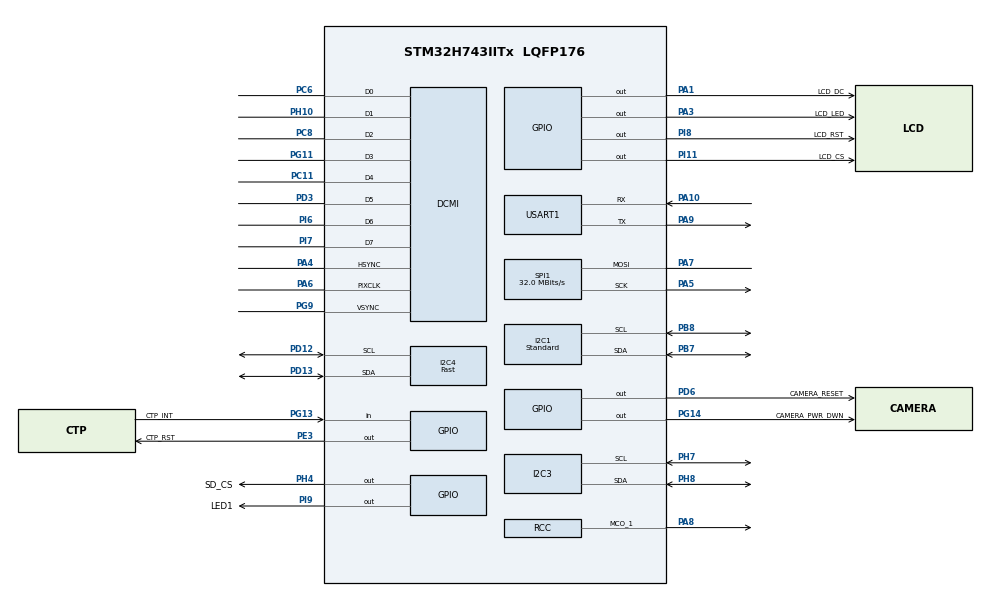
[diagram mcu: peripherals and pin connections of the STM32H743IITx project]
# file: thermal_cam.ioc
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CORTEX_M7.CPU_DCache=Disabled
CORTEX_M7.CPU_ICache=Disabled
CORTEX_M7.Enable_Spec=__NULL
CORTEX_M7.MPU_Control=__NULL
CORTEX_M7.default_mode_Activation=1
DCMI.HSPolarity=DCMI_HSPOLARITY_LOW
DCMI.PCKPolarity=DCMI_PCKPOLARITY_RISING
DCMI.VSPolarity=DCMI_VSPOLARITY_HIGH
Dma.DCMI.1.Direction=DMA_PERIPH_TO_MEMORY
Dma.DCMI.1.EventEnable=DISABLE
Dma.DCMI.1.FIFOMode=DMA_FIFOMODE_DISABLE
Dma.DCMI.1.Instance=DMA1_Stream2
Dma.DCMI.1.MemDataAlignment=DMA_MDATAALIGN_WORD
Dma.DCMI.1.MemInc=DMA_MINC_ENABLE
Dma.DCMI.1.Mode=DMA_NORMAL
Dma.DCMI.1.PeriphDataAlignment=DMA_PDATAALIGN_WORD
Dma.DCMI.1.PeriphInc=DMA_PINC_DISABLE
Dma.DCMI.1.Polarity=HAL_DMAMUX_REQ_GEN_RISING
Dma.DCMI.1.Priority=DMA_PRIORITY_LOW
Dma.DCMI.1.RequestNumber=1
Dma.DCMI.1.SignalID=NONE
Dma.DCMI.1.SyncEnable=DISABLE
Dma.DCMI.1.SyncPolarity=HAL_DMAMUX_SYNC_NO_EVENT
Dma.DCMI.1.SyncRequestNumber=1
Dma.DCMI.1.SyncSignalID=NONE
Dma.Request0=USART1_RX
Dma.Request1=DCMI
Dma.Request2=SPI1_TX
Dma.SPI1_TX.2.Direction=DMA_MEMORY_TO_PERIPH
Dma.SPI1_TX.2.EventEnable=DISABLE
Dma.SPI1_TX.2.FIFOMode=DMA_FIFOMODE_DISABLE
Dma.SPI1_TX.2.Instance=DMA1_Stream1
Dma.SPI1_TX.2.MemDataAlignment=DMA_MDATAALIGN_HALFWORD
Dma.SPI1_TX.2.MemInc=DMA_MINC_ENABLE
Dma.SPI1_TX.2.Mode=DMA_NORMAL
Dma.SPI1_TX.2.PeriphDataAlignment=DMA_PDATAALIGN_HALFWORD
Dma.SPI1_TX.2.PeriphInc=DMA_PINC_DISABLE
Dma.SPI1_TX.2.Polarity=HAL_DMAMUX_REQ_GEN_RISING
Dma.SPI1_TX.2.Priority=DMA_PRIORITY_LOW
Dma.SPI1_TX.2.RequestNumber=1
Dma.SPI1_TX.2.SignalID=NONE
Dma.SPI1_TX.2.SyncEnable=DISABLE
Dma.SPI1_TX.2.SyncPolarity=HAL_DMAMUX_SYNC_NO_EVENT
Dma.SPI1_TX.2.SyncRequestNumber=1
Dma.SPI1_TX.2.SyncSignalID=NONE
Dma.USART1_RX.0.Direction=DMA_PERIPH_TO_MEMORY
Dma.USART1_RX.0.EventEnable=DISABLE
Dma.USART1_RX.0.FIFOMode=DMA_FIFOMODE_DISABLE
Dma.USART1_RX.0.Instance=DMA1_Stream0
Dma.USART1_RX.0.MemDataAlignment=DMA_MDATAALIGN_BYTE
Dma.USART1_RX.0.MemInc=DMA_MINC_ENABLE
Dma.USART1_RX.0.Mode=DMA_CIRCULAR
Dma.USART1_RX.0.PeriphDataAlignment=DMA_PDATAALIGN_BYTE
Dma.USART1_RX.0.PeriphInc=DMA_PINC_DISABLE
Dma.USART1_RX.0.Polarity=HAL_DMAMUX_REQ_GEN_RISING
Dma.USART1_RX.0.Priority=DMA_PRIORITY_LOW
Dma.USART1_RX.0.RequestNumber=1
Dma.USART1_RX.0.SignalID=NONE
Dma.USART1_RX.0.SyncEnable=DISABLE
Dma.USART1_RX.0.SyncPolarity=HAL_DMAMUX_SYNC_NO_EVENT
Dma.USART1_RX.0.SyncRequestNumber=1
Dma.USART1_RX.0.SyncSignalID=NONE
FREERTOS.BinarySemaphores01=thermalSem,Dynamic,NULL,Depleted;RGBSem,Dynamic,NULL,Depleted
FREERTOS.Tasks01=defaultTask,24,128,StartDefaultTask,Default,NULL,Dynamic,NULL,NULL;cli_thread,24,256,cliThread,As external,NULL,Dynamic,NULL,NULL;lvgl_thread,32,6144,lvglThread,As external,NULL,Dynamic,NULL,NULL;thermal_thread,24,1024,thermalThread,As external,NULL,Dynamic,NULL,NULL;RGB_thread,24,2048,RGBThread,As external,NULL,Dynamic,NULL,NULL;BPM_Thread,24,2048,BPMThread,As external,NULL,Dynamic,NULL,NULL;BPM_Thread2,24,1024,BPMThread2,As external,NULL,Dynamic,NULL,NULL
FREERTOS.configCHECK_FOR_STACK_OVERFLOW=2
FREERTOS.configENABLE_FPU=1
FREERTOS.configTOTAL_HEAP_SIZE=64000
FREERTOS.configUSE_MALLOC_FAILED_HOOK=1
FREERTOS.configUSE_NEWLIB_REENTRANT=1
I2C1.I2C_Speed_Mode=I2C_Standard
I2C1.Timing=0x307075B1
I2C3.Timing=0x307075B1
I2C4.I2C_Speed_Mode=I2C_Fast
I2C4.Timing=0x00B03FDB
Mcu.Family=STM32H7
Mcu.Name=STM32H743IITx
Mcu.Package=LQFP176
NVIC.DCMI_IRQn=true\:5\:0\:false\:false\:true\:true\:true\:true\:true
NVIC.DMA1_Stream0_IRQn=true\:5\:0\:false\:false\:true\:true\:false\:true\:true
NVIC.DMA1_Stream1_IRQn=true\:5\:0\:false\:false\:true\:true\:false\:true\:true
NVIC.DMA1_Stream2_IRQn=true\:5\:0\:false\:false\:true\:true\:false\:true\:true
NVIC.PriorityGroup=NVIC_PRIORITYGROUP_4
NVIC.SPI1_IRQn=true\:5\:0\:false\:false\:true\:true\:false\:true\:true
NVIC.TIM16_IRQn=true\:5\:0\:false\:false\:true\:true\:true\:true\:true
NVIC.TIM7_IRQn=true\:15\:0\:false\:false\:true\:false\:false\:true\:true
NVIC.TimeBase=TIM7_IRQn
NVIC.TimeBaseIP=TIM7
PA1.GPIO_Label=LCD_DC
PA1.GPIO_Speed=GPIO_SPEED_FREQ_LOW
PA1.PinState=GPIO_PIN_RESET
PA1.Signal=GPIO_Output
PA10.Mode=Asynchronous
PA10.PinAttribute=Free
PA10.Signal=USART1_RX
PA13\ (JTMS/SWDIO).Mode=Serial_Wire
PA13\ (JTMS/SWDIO).PinAttribute=Free
PA13\ (JTMS/SWDIO).Signal=DEBUG_JTMS-SWDIO
PA14\ (JTCK/SWCLK).Mode=Serial_Wire
PA14\ (JTCK/SWCLK).PinAttribute=Free
PA14\ (JTCK/SWCLK).Signal=DEBUG_JTCK-SWCLK
PA3.GPIO_Label=LCD_LED
PA3.Signal=GPIO_Output
PA4.GPIO_PuPd=GPIO_NOPULL
PA4.GPIO_Speed=GPIO_SPEED_FREQ_LOW
PA4.Mode=Slave_8_bits_External_Synchro
PA4.Signal=DCMI_HSYNC
PA5.Mode=Simplex_Bidirectional_Master
PA5.Signal=SPI1_SCK
PA6.GPIO_PuPd=GPIO_NOPULL
PA6.GPIO_Speed=GPIO_SPEED_FREQ_LOW
PA6.Mode=Slave_8_bits_External_Synchro
PA6.Signal=DCMI_PIXCLK
PA7.GPIO_Speed=GPIO_SPEED_FREQ_LOW
PA7.Mode=Simplex_Bidirectional_Master
PA7.Signal=SPI1_MOSI
PA8.Mode=Clock-out-1
PA8.Signal=RCC_MCO_1
PA9.Mode=Asynchronous
PA9.PinAttribute=Free
PA9.Signal=USART1_TX
PB7.GPIO_Pu=GPIO_NOPULL
PB7.GPIO_Speed=GPIO_SPEED_FREQ_LOW
PB7.Mode=I2C
PB7.Signal=I2C1_SDA
PB8.GPIO_Pu=GPIO_NOPULL
PB8.GPIO_Speed=GPIO_SPEED_FREQ_LOW
PB8.Mode=I2C
PB8.Signal=I2C1_SCL
PC11.GPIO_PuPd=GPIO_NOPULL
PC11.GPIO_Speed=GPIO_SPEED_FREQ_LOW
PC11.Mode=Slave_8_bits_External_Synchro
PC11.Signal=DCMI_D4
PC14-OSC32_IN\ (OSC32_IN).Mode=LSE-External-Oscillator
PC14-OSC32_IN\ (OSC32_IN).Signal=RCC_OSC32_IN
PC15-OSC32_OUT\ (OSC32_OUT).Mode=LSE-External-Oscillator
PC15-OSC32_OUT\ (OSC32_OUT).Signal=RCC_OSC32_OUT
PC6.GPIO_PuPd=GPIO_NOPULL
PC6.GPIO_Speed=GPIO_SPEED_FREQ_LOW
PC6.Mode=Slave_8_bits_External_Synchro
PC6.PinAttribute=Free
PC6.Signal=DCMI_D0
PC8.GPIO_PuPd=GPIO_NOPULL
PC8.GPIO_Speed=GPIO_SPEED_FREQ_LOW
PC8.Mode=Slave_8_bits_External_Synchro
PC8.PinAttribute=Free
PC8.Signal=DCMI_D2
PD12.Mode=I2C
PD12.PinAttribute=Free
PD12.Signal=I2C4_SCL
PD13.Mode=I2C
PD13.PinAttribute=Free
PD13.Signal=I2C4_SDA
PD3.GPIO_PuPd=GPIO_NOPULL
PD3.GPIO_Speed=GPIO_SPEED_FREQ_LOW
PD3.Mode=Slave_8_bits_External_Synchro
PD3.PinAttribute=Free
PD3.Signal=DCMI_D5
PD6.GPIO_Label=CAMERA_RESET
PD6.Signal=GPIO_Output
PE3.GPIO_Label=CTP_RST
PE3.PinState=GPIO_PIN_SET
PE3.Signal=GPIO_Output
PG11.GPIO_PuPd=GPIO_NOPULL
PG11.GPIO_Speed=GPIO_SPEED_FREQ_LOW
PG11.Mode=Slave_8_bits_External_Synchro
PG11.Signal=DCMI_D3
PG13.GPIO_Label=CTP_INT
PG13.GPIO_PuPd=GPIO_PULLUP
PG13.Signal=GPIO_Input
PG14.GPIO_Label=CAMERA_PWR_DWN
PG14.Signal=GPIO_Output
PG9.GPIO_PuPd=GPIO_NOPULL
PG9.GPIO_Speed=GPIO_SPEED_FREQ_LOW
PG9.Mode=Slave_8_bits_External_Synchro
PG9.PinAttribute=Free
PG9.Signal=DCMI_VSYNC
PH0-OSC_IN\ (PH0).Mode=HSE-External-Oscillator
PH0-OSC_IN\ (PH0).Signal=RCC_OSC_IN
PH1-OSC_OUT\ (PH1).Mode=HSE-External-Oscillator
PH1-OSC_OUT\ (PH1).Signal=RCC_OSC_OUT
PH10.GPIO_PuPd=GPIO_NOPULL
PH10.GPIO_Speed=GPIO_SPEED_FREQ_LOW
PH10.Mode=Slave_8_bits_External_Synchro
PH10.PinAttribute=Free
PH10.Signal=DCMI_D1
PH2.Signal=FMC_SDCKE0
PH3.Signal=FMC_SDNE0
PH4.GPIO_Label=SD_CS
PH4.PinState=GPIO_PIN_SET
PH4.Signal=GPIO_Output
PH5.Signal=FMC_SDNWE
PH7.GPIO_Pu=GPIO_PULLUP
PH7.Mode=I2C
PH7.Signal=I2C3_SCL
PH8.GPIO_Pu=GPIO_PULLUP
PH8.Mode=I2C
PH8.Signal=I2C3_SDA
PI11.GPIO_Label=LCD_CS
PI11.GPIO_Speed=GPIO_SPEED_FREQ_LOW
PI11.Signal=GPIO_Output
PI6.GPIO_PuPd=GPIO_NOPULL
PI6.GPIO_Speed=GPIO_SPEED_FREQ_LOW
PI6.Mode=Slave_8_bits_External_Synchro
PI6.Signal=DCMI_D6
PI7.GPIO_PuPd=GPIO_NOPULL
PI7.GPIO_Speed=GPIO_SPEED_FREQ_LOW
PI7.Mode=Slave_8_bits_External_Synchro
PI7.Signal=DCMI_D7
PI8.GPIO_Label=LCD_RST
PI8.Signal=GPIO_Output
PI9.GPIO_Label=LED1
PI9.Signal=GPIO_Output
ProjectManager.HeapSize=0x200
ProjectManager.StackSize=0x400
ProjectManager.TargetToolchain=STM32CubeIDE
RCC.ADCFreq_Value=75000000
RCC.APB1Freq_Value=120000000
RCC.APB2Freq_Value=120000000
RCC.APB3Freq_Value=120000000
RCC.APB4Freq_Value=120000000
RCC.CortexFreq_Value=480000000
RCC.D1PPRE=RCC_APB3_DIV2
RCC.D2PPRE1=RCC_APB1_DIV2
RCC.D2PPRE2=RCC_APB2_DIV2
RCC.D3PPRE=RCC_APB4_DIV2
RCC.DIVM1=5
RCC.DIVM2=2
RCC.DIVN1=192
RCC.DIVN2=12
RCC.DIVQ1=15
RCC.HCLKFreq_Value=240000000
RCC.HPRE=RCC_HCLK_DIV2
RCC.PLL1_VCI_Range=RCC_PLL1VCIRANGE_2
RCC.PLL3_VCO_SEL-AdvancedSettings=RCC_PLL3VCOWIDE
RCC.PLLFRACN=0
RCC.PLLSourceVirtual=RCC_PLLSOURCE_HSE
RCC.RCC_MCO1Source=RCC_MCO1SOURCE_HSE
RCC.RCC_MCODiv2=RCC_MCODIV_15
RCC.SYSCLKFreq_VALUE=480000000
RCC.SYSCLKSource=RCC_SYSCLKSOURCE_PLLCLK
RCC.USBFreq_Value=64000000
SH.FMC_SDNWE.0=FMC_SDNWE
SPI1.BaudRatePrescaler=SPI_BAUDRATEPRESCALER_2
SPI1.CalculateBaudRate=32.0 MBits/s
SPI1.DataSize=SPI_DATASIZE_8BIT
SPI1.Direction=SPI_DIRECTION_1LINE
SPI1.Mode=SPI_MODE_MASTER
SPI1.VirtualType=VM_MASTER
TIM16.AutoReloadPreload=TIM_AUTORELOAD_PRELOAD_ENABLE
TIM16.Period=624
TIM16.Prescaler=24999
USART1.VirtualMode-Asynchronous=VM_ASYNC
VP_FREERTOS_VS_CMSIS_V2.Mode=CMSIS_V2
VP_MEMORYMAP_VS_MEMORYMAP.Mode=CurAppReg
VP_SYS_VS_tim7.Mode=TIM7
VP_TIM16_VS_ClockSourceINT.Mode=Enable_Timer
board=custom

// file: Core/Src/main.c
/* USER CODE BEGIN Header */
/**
  ******************************************************************************
  * @file           : main.c
  * @brief          : Main program body
  ******************************************************************************
  * @attention
  *
  * Copyright (c) 2025 STMicroelectronics.
  * All rights reserved.
  *
  * This software is licensed under terms that can be found in the LICENSE file
  * in the root directory of this software component.
  * If no LICENSE file comes with this software, it is provided AS-IS.
  *
  ******************************************************************************
  */
/* USER CODE END Header */
#include "main.h"
#include "cmsis_os.h"

/* USER CODE BEGIN Includes */
#include "ap.h"
/* USER CODE END Includes */

DCMI_HandleTypeDef hdcmi;
DMA_HandleTypeDef hdma_dcmi;

I2C_HandleTypeDef hi2c1;
I2C_HandleTypeDef hi2c3;
I2C_HandleTypeDef hi2c4;

SPI_HandleTypeDef hspi1;
DMA_HandleTypeDef hdma_spi1_tx;

TIM_HandleTypeDef htim16;

UART_HandleTypeDef huart1;
DMA_HandleTypeDef hdma_usart1_rx;

/* Definitions for defaultTask */
osThreadId_t defaultTaskHandle;
const osThreadAttr_t defaultTask_attributes = {
  .name = "defaultTask",
  .stack_size = 128 * 4,
  .priority = (osPriority_t) osPriorityNormal,
};
/* Definitions for cli_thread */
osThreadId_t cli_threadHandle;
const osThreadAttr_t cli_thread_attributes = {
  .name = "cli_thread",
  .stack_size = 256 * 4,
  .priority = (osPriority_t) osPriorityNormal,
};
/* Definitions for lvgl_thread */
osThreadId_t lvgl_threadHandle;
const osThreadAttr_t lvgl_thread_attributes = {
  .name = "lvgl_thread",
  .stack_size = 6144 * 4,
  .priority = (osPriority_t) osPriorityAboveNormal,
};
/* Definitions for thermal_thread */
osThreadId_t thermal_threadHandle;
const osThreadAttr_t thermal_thread_attributes = {
  .name = "thermal_thread",
  .stack_size = 1024 * 4,
  .priority = (osPriority_t) osPriorityNormal,
};
/* Definitions for RGB_thread */
osThreadId_t RGB_threadHandle;
const osThreadAttr_t RGB_thread_attributes = {
  .name = "RGB_thread",
  .stack_size = 2048 * 4,
  .priority = (osPriority_t) osPriorityNormal,
};
/* Definitions for BPM_Thread */
osThreadId_t BPM_ThreadHandle;
const osThreadAttr_t BPM_Thread_attributes = {
  .name = "BPM_Thread",
  .stack_size = 2048 * 4,
  .priority = (osPriority_t) osPriorityNormal,
};
/* Definitions for BPM_Thread2 */
osThreadId_t BPM_Thread2Handle;
const osThreadAttr_t BPM_Thread2_attributes = {
  .name = "BPM_Thread2",
  .stack_size = 1024 * 4,
  .priority = (osPriority_t) osPriorityNormal,
};
/* Definitions for thermalSem */
osSemaphoreId_t thermalSemHandle;
const osSemaphoreAttr_t thermalSem_attributes = {
  .name = "thermalSem"
};
/* Definitions for RGBSem */
osSemaphoreId_t RGBSemHandle;
const osSemaphoreAttr_t RGBSem_attributes = {
  .name = "RGBSem"
};

void SystemClock_Config(void);
static void MX_GPIO_Init(void);
static void MX_DMA_Init(void);
static void MX_USART1_UART_Init(void);
static void MX_DCMI_Init(void);
static void MX_I2C3_Init(void);
static void MX_I2C4_Init(void);
static void MX_SPI1_Init(void);
static void MX_I2C1_Init(void);
static void MX_TIM16_Init(void);
void StartDefaultTask(void *argument);
extern void cliThread(void *argument);
extern void lvglThread(void *argument);
extern void thermalThread(void *argument);
extern void RGBThread(void *argument);
extern void BPMThread(void *argument);
extern void BPMThread2(void *argument);

int main(void)
{

  /* MCU Configuration--------------------------------------------------------*/

  /* Reset of all peripherals, Initializes the Flash interface and the Systick. */
  HAL_Init();

  /* Configure the system clock */
  SystemClock_Config();

  /* Initialize all configured peripherals */
  MX_GPIO_Init();
  MX_DMA_Init();
  MX_USART1_UART_Init();
  MX_DCMI_Init();
  MX_I2C3_Init();
  MX_I2C4_Init();
  MX_SPI1_Init();
  MX_I2C1_Init();
  MX_TIM16_Init();
  /* USER CODE BEGIN 2 */
  delay(100);
  hwInit();
  apInit();

  /* USER CODE END 2 */

  /* Init scheduler */
  osKernelInitialize();

  /* Create the semaphores(s) */
  /* creation of thermalSem */
  thermalSemHandle = osSemaphoreNew(1, 0, &thermalSem_attributes);

  /* creation of RGBSem */
  RGBSemHandle = osSemaphoreNew(1, 0, &RGBSem_attributes);

  /* Create the thread(s) */
  /* creation of defaultTask */
  defaultTaskHandle = osThreadNew(StartDefaultTask, NULL, &defaultTask_attributes);

  /* creation of cli_thread */
  cli_threadHandle = osThreadNew(cliThread, NULL, &cli_thread_attributes);

  /* creation of lvgl_thread */
  lvgl_threadHandle = osThreadNew(lvglThread, NULL, &lvgl_thread_attributes);

  /* creation of thermal_thread */
  thermal_threadHandle = osThreadNew(thermalThread, NULL, &thermal_thread_attributes);

  /* creation of RGB_thread */
  RGB_threadHandle = osThreadNew(RGBThread, NULL, &RGB_thread_attributes);

  /* creation of BPM_Thread */
  BPM_ThreadHandle = osThreadNew(BPMThread, NULL, &BPM_Thread_attributes);

  /* creation of BPM_Thread2 */
  BPM_Thread2Handle = osThreadNew(BPMThread2, NULL, &BPM_Thread2_attributes);

  /* Start scheduler */
  osKernelStart();

  /* We should never get here as control is now taken by the scheduler */

  /* Infinite loop */
  while (1)
  {

  }
}

void SystemClock_Config(void)
{
  RCC_OscInitTypeDef RCC_OscInitStruct = {0};
  RCC_ClkInitTypeDef RCC_ClkInitStruct = {0};

  /** Supply configuration update enable
  */
  HAL_PWREx_ConfigSupply(PWR_LDO_SUPPLY);

  /** Configure the main internal regulator output voltage
  */
  __HAL_PWR_VOLTAGESCALING_CONFIG(PWR_REGULATOR_VOLTAGE_SCALE0);

  while(!__HAL_PWR_GET_FLAG(PWR_FLAG_VOSRDY)) {}

  /** Initializes the RCC Oscillators according to the specified parameters
  * in the RCC_OscInitTypeDef structure.
  */
  RCC_OscInitStruct.OscillatorType = RCC_OSCILLATORTYPE_HSE;
  RCC_OscInitStruct.HSEState = RCC_HSE_ON;
  RCC_OscInitStruct.PLL.PLLState = RCC_PLL_ON;
  RCC_OscInitStruct.PLL.PLLSource = RCC_PLLSOURCE_HSE;
  RCC_OscInitStruct.PLL.PLLM = 5;
  RCC_OscInitStruct.PLL.PLLN = 192;
  RCC_OscInitStruct.PLL.PLLP = 2;
  RCC_OscInitStruct.PLL.PLLQ = 15;
  RCC_OscInitStruct.PLL.PLLR = 2;
  RCC_OscInitStruct.PLL.PLLRGE = RCC_PLL1VCIRANGE_2;
  RCC_OscInitStruct.PLL.PLLVCOSEL = RCC_PLL1VCOWIDE;
  RCC_OscInitStruct.PLL.PLLFRACN = 0;
  if (HAL_RCC_OscConfig(&RCC_OscInitStruct) != HAL_OK)
  {
    Error_Handler();
  }

  /** Initializes the CPU, AHB and APB buses clocks
  */
  RCC_ClkInitStruct.ClockType = RCC_CLOCKTYPE_HCLK|RCC_CLOCKTYPE_SYSCLK
                              |RCC_CLOCKTYPE_PCLK1|RCC_CLOCKTYPE_PCLK2
                              |RCC_CLOCKTYPE_D3PCLK1|RCC_CLOCKTYPE_D1PCLK1;
  RCC_ClkInitStruct.SYSCLKSource = RCC_SYSCLKSOURCE_PLLCLK;
  RCC_ClkInitStruct.SYSCLKDivider = RCC_SYSCLK_DIV1;
  RCC_ClkInitStruct.AHBCLKDivider = RCC_HCLK_DIV2;
  RCC_ClkInitStruct.APB3CLKDivider = RCC_APB3_DIV2;
  RCC_ClkInitStruct.APB1CLKDivider = RCC_APB1_DIV2;
  RCC_ClkInitStruct.APB2CLKDivider = RCC_APB2_DIV2;
  RCC_ClkInitStruct.APB4CLKDivider = RCC_APB4_DIV2;

  if (HAL_RCC_ClockConfig(&RCC_ClkInitStruct, FLASH_LATENCY_4) != HAL_OK)
  {
    Error_Handler();
  }
  HAL_RCC_MCOConfig(RCC_MCO1, RCC_MCO1SOURCE_HSE, RCC_MCODIV_1);
}

static void MX_DCMI_Init(void)
{

  hdcmi.Instance = DCMI;
  hdcmi.Init.SynchroMode = DCMI_SYNCHRO_HARDWARE;
  hdcmi.Init.PCKPolarity = DCMI_PCKPOLARITY_RISING;
  hdcmi.Init.VSPolarity = DCMI_VSPOLARITY_HIGH;
  hdcmi.Init.HSPolarity = DCMI_HSPOLARITY_LOW;
  hdcmi.Init.CaptureRate = DCMI_CR_ALL_FRAME;
  hdcmi.Init.ExtendedDataMode = DCMI_EXTEND_DATA_8B;
  hdcmi.Init.JPEGMode = DCMI_JPEG_DISABLE;
  hdcmi.Init.ByteSelectMode = DCMI_BSM_ALL;
  hdcmi.Init.ByteSelectStart = DCMI_OEBS_ODD;
  hdcmi.Init.LineSelectMode = DCMI_LSM_ALL;
  hdcmi.Init.LineSelectStart = DCMI_OELS_ODD;
  if (HAL_DCMI_Init(&hdcmi) != HAL_OK)
  {
    Error_Handler();
  }

}

static void MX_I2C1_Init(void)
{

  hi2c1.Instance = I2C1;
  hi2c1.Init.Timing = 0x307075B1;
  hi2c1.Init.OwnAddress1 = 0;
  hi2c1.Init.AddressingMode = I2C_ADDRESSINGMODE_7BIT;
  hi2c1.Init.DualAddressMode = I2C_DUALADDRESS_DISABLE;
  hi2c1.Init.OwnAddress2 = 0;
  hi2c1.Init.OwnAddress2Masks = I2C_OA2_NOMASK;
  hi2c1.Init.GeneralCallMode = I2C_GENERALCALL_DISABLE;
  hi2c1.Init.NoStretchMode = I2C_NOSTRETCH_DISABLE;
  if (HAL_I2C_Init(&hi2c1) != HAL_OK)
  {
    Error_Handler();
  }

  /** Configure Analogue filter
  */
  if (HAL_I2CEx_ConfigAnalogFilter(&hi2c1, I2C_ANALOGFILTER_ENABLE) != HAL_OK)
  {
    Error_Handler();
  }

  /** Configure Digital filter
  */
  if (HAL_I2CEx_ConfigDigitalFilter(&hi2c1, 0) != HAL_OK)
  {
    Error_Handler();
  }

}

static void MX_I2C3_Init(void)
{

  hi2c3.Instance = I2C3;
  hi2c3.Init.Timing = 0x307075B1;
  hi2c3.Init.OwnAddress1 = 0;
  hi2c3.Init.AddressingMode = I2C_ADDRESSINGMODE_7BIT;
  hi2c3.Init.DualAddressMode = I2C_DUALADDRESS_DISABLE;
  hi2c3.Init.OwnAddress2 = 0;
  hi2c3.Init.OwnAddress2Masks = I2C_OA2_NOMASK;
  hi2c3.Init.GeneralCallMode = I2C_GENERALCALL_DISABLE;
  hi2c3.Init.NoStretchMode = I2C_NOSTRETCH_DISABLE;
  if (HAL_I2C_Init(&hi2c3) != HAL_OK)
  {
    Error_Handler();
  }

  /** Configure Analogue filter
  */
  if (HAL_I2CEx_ConfigAnalogFilter(&hi2c3, I2C_ANALOGFILTER_ENABLE) != HAL_OK)
  {
    Error_Handler();
  }

  /** Configure Digital filter
  */
  if (HAL_I2CEx_ConfigDigitalFilter(&hi2c3, 0) != HAL_OK)
  {
    Error_Handler();
  }

}

static void MX_I2C4_Init(void)
{

  hi2c4.Instance = I2C4;
  hi2c4.Init.Timing = 0x00B03FDB;
  hi2c4.Init.OwnAddress1 = 0;
  hi2c4.Init.AddressingMode = I2C_ADDRESSINGMODE_7BIT;
  hi2c4.Init.DualAddressMode = I2C_DUALADDRESS_DISABLE;
  hi2c4.Init.OwnAddress2 = 0;
  hi2c4.Init.OwnAddress2Masks = I2C_OA2_NOMASK;
  hi2c4.Init.GeneralCallMode = I2C_GENERALCALL_DISABLE;
  hi2c4.Init.NoStretchMode = I2C_NOSTRETCH_DISABLE;
  if (HAL_I2C_Init(&hi2c4) != HAL_OK)
  {
    Error_Handler();
  }

  /** Configure Analogue filter
  */
  if (HAL_I2CEx_ConfigAnalogFilter(&hi2c4, I2C_ANALOGFILTER_ENABLE) != HAL_OK)
  {
    Error_Handler();
  }

  /** Configure Digital filter
  */
  if (HAL_I2CEx_ConfigDigitalFilter(&hi2c4, 0) != HAL_OK)
  {
    Error_Handler();
  }

}

static void MX_SPI1_Init(void)
{

  /* SPI1 parameter configuration*/
  hspi1.Instance = SPI1;
  hspi1.Init.Mode = SPI_MODE_MASTER;
  hspi1.Init.Direction = SPI_DIRECTION_1LINE;
  hspi1.Init.DataSize = SPI_DATASIZE_8BIT;
  hspi1.Init.CLKPolarity = SPI_POLARITY_LOW;
  hspi1.Init.CLKPhase = SPI_PHASE_1EDGE;
  hspi1.Init.NSS = SPI_NSS_SOFT;
  hspi1.Init.BaudRatePrescaler = SPI_BAUDRATEPRESCALER_2;
  hspi1.Init.FirstBit = SPI_FIRSTBIT_MSB;
  hspi1.Init.TIMode = SPI_TIMODE_DISABLE;
  hspi1.Init.CRCCalculation = SPI_CRCCALCULATION_DISABLE;
  hspi1.Init.CRCPolynomial = 0x0;
  hspi1.Init.NSSPMode = SPI_NSS_PULSE_ENABLE;
  hspi1.Init.NSSPolarity = SPI_NSS_POLARITY_LOW;
  hspi1.Init.FifoThreshold = SPI_FIFO_THRESHOLD_01DATA;
  hspi1.Init.TxCRCInitializationPattern = SPI_CRC_INITIALIZATION_ALL_ZERO_PATTERN;
  hspi1.Init.RxCRCInitializationPattern = SPI_CRC_INITIALIZATION_ALL_ZERO_PATTERN;
  hspi1.Init.MasterSSIdleness = SPI_MASTER_SS_IDLENESS_00CYCLE;
  hspi1.Init.MasterInterDataIdleness = SPI_MASTER_INTERDATA_IDLENESS_00CYCLE;
  hspi1.Init.MasterReceiverAutoSusp = SPI_MASTER_RX_AUTOSUSP_DISABLE;
  hspi1.Init.MasterKeepIOState = SPI_MASTER_KEEP_IO_STATE_DISABLE;
  hspi1.Init.IOSwap = SPI_IO_SWAP_DISABLE;
  if (HAL_SPI_Init(&hspi1) != HAL_OK)
  {
    Error_Handler();
  }

}

static void MX_TIM16_Init(void)
{

  htim16.Instance = TIM16;
  htim16.Init.Prescaler = 24999;
  htim16.Init.CounterMode = TIM_COUNTERMODE_UP;
  htim16.Init.Period = 624;
  htim16.Init.ClockDivision = TIM_CLOCKDIVISION_DIV1;
  htim16.Init.RepetitionCounter = 0;
  htim16.Init.AutoReloadPreload = TIM_AUTORELOAD_PRELOAD_ENABLE;
  if (HAL_TIM_Base_Init(&htim16) != HAL_OK)
  {
    Error_Handler();
  }

}

static void MX_USART1_UART_Init(void)
{

  huart1.Instance = USART1;
  huart1.Init.BaudRate = 115200;
  huart1.Init.WordLength = UART_WORDLENGTH_8B;
  huart1.Init.StopBits = UART_STOPBITS_1;
  huart1.Init.Parity = UART_PARITY_NONE;
  huart1.Init.Mode = UART_MODE_TX_RX;
  huart1.Init.HwFlowCtl = UART_HWCONTROL_NONE;
  huart1.Init.OverSampling = UART_OVERSAMPLING_16;
  huart1.Init.OneBitSampling = UART_ONE_BIT_SAMPLE_DISABLE;
  huart1.Init.ClockPrescaler = UART_PRESCALER_DIV1;
  huart1.AdvancedInit.AdvFeatureInit = UART_ADVFEATURE_NO_INIT;
  if (HAL_UART_Init(&huart1) != HAL_OK)
  {
    Error_Handler();
  }
  if (HAL_UARTEx_SetTxFifoThreshold(&huart1, UART_TXFIFO_THRESHOLD_1_8) != HAL_OK)
  {
    Error_Handler();
  }
  if (HAL_UARTEx_SetRxFifoThreshold(&huart1, UART_RXFIFO_THRESHOLD_1_8) != HAL_OK)
  {
    Error_Handler();
  }
  if (HAL_UARTEx_DisableFifoMode(&huart1) != HAL_OK)
  {
    Error_Handler();
  }

}

static void MX_DMA_Init(void)
{

  /* DMA controller clock enable */
  __HAL_RCC_DMA1_CLK_ENABLE();

  /* DMA interrupt init */
  /* DMA1_Stream0_IRQn interrupt configuration */
  HAL_NVIC_SetPriority(DMA1_Stream0_IRQn, 5, 0);
  HAL_NVIC_EnableIRQ(DMA1_Stream0_IRQn);
  /* DMA1_Stream1_IRQn interrupt configuration */
  HAL_NVIC_SetPriority(DMA1_Stream1_IRQn, 5, 0);
  HAL_NVIC_EnableIRQ(DMA1_Stream1_IRQn);
  /* DMA1_Stream2_IRQn interrupt configuration */
  HAL_NVIC_SetPriority(DMA1_Stream2_IRQn, 5, 0);
  HAL_NVIC_EnableIRQ(DMA1_Stream2_IRQn);

}

static void MX_GPIO_Init(void)
{
  GPIO_InitTypeDef GPIO_InitStruct = {0};

  /* GPIO Ports Clock Enable */
  __HAL_RCC_GPIOE_CLK_ENABLE();
  __HAL_RCC_GPIOI_CLK_ENABLE();
  __HAL_RCC_GPIOC_CLK_ENABLE();
  __HAL_RCC_GPIOH_CLK_ENABLE();
  __HAL_RCC_GPIOA_CLK_ENABLE();
  __HAL_RCC_GPIOD_CLK_ENABLE();
  __HAL_RCC_GPIOG_CLK_ENABLE();
  __HAL_RCC_GPIOB_CLK_ENABLE();

  /*Configure GPIO pin Output Level */
  HAL_GPIO_WritePin(CTP_RST_GPIO_Port, CTP_RST_Pin, GPIO_PIN_SET);

  /*Configure GPIO pin Output Level */
  HAL_GPIO_WritePin(GPIOI, LCD_RST_Pin|LED1_Pin|LCD_CS_Pin, GPIO_PIN_RESET);

  /*Configure GPIO pin Output Level */
  HAL_GPIO_WritePin(GPIOA, LCD_DC_Pin|LCD_LED_Pin, GPIO_PIN_RESET);

  /*Configure GPIO pin Output Level */
  HAL_GPIO_WritePin(SD_CS_GPIO_Port, SD_CS_Pin, GPIO_PIN_SET);

  /*Configure GPIO pin Output Level */
  HAL_GPIO_WritePin(CAMERA_RESET_GPIO_Port, CAMERA_RESET_Pin, GPIO_PIN_RESET);

  /*Configure GPIO pin Output Level */
  HAL_GPIO_WritePin(CAMERA_PWR_DWN_GPIO_Port, CAMERA_PWR_DWN_Pin, GPIO_PIN_RESET);

  /*Configure GPIO pin : CTP_RST_Pin */
  GPIO_InitStruct.Pin = CTP_RST_Pin;
  GPIO_InitStruct.Mode = GPIO_MODE_OUTPUT_PP;
  GPIO_InitStruct.Pull = GPIO_NOPULL;
  GPIO_InitStruct.Speed = GPIO_SPEED_FREQ_LOW;
  HAL_GPIO_Init(CTP_RST_GPIO_Port, &GPIO_InitStruct);

  /*Configure GPIO pins : LCD_RST_Pin LED1_Pin LCD_CS_Pin */
  GPIO_InitStruct.Pin = LCD_RST_Pin|LED1_Pin|LCD_CS_Pin;
  GPIO_InitStruct.Mode = GPIO_MODE_OUTPUT_PP;
  GPIO_InitStruct.Pull = GPIO_NOPULL;
  GPIO_InitStruct.Speed = GPIO_SPEED_FREQ_LOW;
  HAL_GPIO_Init(GPIOI, &GPIO_InitStruct);

  /*Configure GPIO pins : LCD_DC_Pin LCD_LED_Pin */
  GPIO_InitStruct.Pin = LCD_DC_Pin|LCD_LED_Pin;
  GPIO_InitStruct.Mode = GPIO_MODE_OUTPUT_PP;
  GPIO_InitStruct.Pull = GPIO_NOPULL;
  GPIO_InitStruct.Speed = GPIO_SPEED_FREQ_LOW;
  HAL_GPIO_Init(GPIOA, &GPIO_InitStruct);

  /*Configure GPIO pins : PH2 PH3 PH5 */
  GPIO_InitStruct.Pin = GPIO_PIN_2|GPIO_PIN_3|GPIO_PIN_5;
  GPIO_InitStruct.Mode = GPIO_MODE_AF_PP;
  GPIO_InitStruct.Pull = GPIO_NOPULL;
  GPIO_InitStruct.Speed = GPIO_SPEED_FREQ_VERY_HIGH;
  GPIO_InitStruct.Alternate = GPIO_AF12_FMC;
  HAL_GPIO_Init(GPIOH, &GPIO_InitStruct);

  /*Configure GPIO pin : SD_CS_Pin */
  GPIO_InitStruct.Pin = SD_CS_Pin;
  GPIO_InitStruct.Mode = GPIO_MODE_OUTPUT_PP;
  GPIO_InitStruct.Pull = GPIO_NOPULL;
  GPIO_InitStruct.Speed = GPIO_SPEED_FREQ_LOW;
  HAL_GPIO_Init(SD_CS_GPIO_Port, &GPIO_InitStruct);

  /*Configure GPIO pin : PA8 */
  GPIO_InitStruct.Pin = GPIO_PIN_8;
  GPIO_InitStruct.Mode = GPIO_MODE_AF_PP;
  GPIO_InitStruct.Pull = GPIO_NOPULL;
  GPIO_InitStruct.Speed = GPIO_SPEED_FREQ_LOW;
  GPIO_InitStruct.Alternate = GPIO_AF0_MCO;
  HAL_GPIO_Init(GPIOA, &GPIO_InitStruct);

  /*Configure GPIO pin : CAMERA_RESET_Pin */
  GPIO_InitStruct.Pin = CAMERA_RESET_Pin;
  GPIO_InitStruct.Mode = GPIO_MODE_OUTPUT_PP;
  GPIO_InitStruct.Pull = GPIO_NOPULL;
  GPIO_InitStruct.Speed = GPIO_SPEED_FREQ_LOW;
  HAL_GPIO_Init(CAMERA_RESET_GPIO_Port, &GPIO_InitStruct);

  /*Configure GPIO pin : CTP_INT_Pin */
  GPIO_InitStruct.Pin = CTP_INT_Pin;
  GPIO_InitStruct.Mode = GPIO_MODE_INPUT;
  GPIO_InitStruct.Pull = GPIO_PULLUP;
  HAL_GPIO_Init(CTP_INT_GPIO_Port, &GPIO_InitStruct);

  /*Configure GPIO pin : CAMERA_PWR_DWN_Pin */
  GPIO_InitStruct.Pin = CAMERA_PWR_DWN_Pin;
  GPIO_InitStruct.Mode = GPIO_MODE_OUTPUT_PP;
  GPIO_InitStruct.Pull = GPIO_NOPULL;
  GPIO_InitStruct.Speed = GPIO_SPEED_FREQ_LOW;
  HAL_GPIO_Init(CAMERA_PWR_DWN_GPIO_Port, &GPIO_InitStruct);

}

void StartDefaultTask(void *argument)
{
  /* USER CODE BEGIN 5 */
  apMain();
  /* Infinite loop */
  for(;;)
  {
    osDelay(1);
  }
  /* USER CODE END 5 */
}

void HAL_TIM_PeriodElapsedCallback(TIM_HandleTypeDef *htim)
{
  if (htim->Instance == TIM7) {
    HAL_IncTick();
  }
  /* USER CODE BEGIN Callback 1 */
   TimerCallback(htim);
  /* USER CODE END Callback 1 */
}

void Error_Handler(void)
{
  __disable_irq();
  while (1)
  {
  }
}

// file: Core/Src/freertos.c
/* USER CODE BEGIN Header */
/**
  ******************************************************************************
  * File Name          : freertos.c
  * Description        : Code for freertos applications
  ******************************************************************************
  * @attention
  *
  * Copyright (c) 2025 STMicroelectronics.
  * All rights reserved.
  *
  * This software is licensed under terms that can be found in the LICENSE file
  * in the root directory of this software component.
  * If no LICENSE file comes with this software, it is provided AS-IS.
  *
  ******************************************************************************
  */
/* USER CODE END Header */

#include "FreeRTOS.h"
#include "task.h"
#include "main.h"

/* USER CODE BEGIN Includes */
#include <stdio.h>
/* USER CODE END Includes */

/* Hook prototypes */
void vApplicationStackOverflowHook(xTaskHandle xTask, signed char *pcTaskName);
void vApplicationMallocFailedHook(void);

/* USER CODE BEGIN 4 */
void vApplicationStackOverflowHook(xTaskHandle xTask, signed char *pcTaskName)
{
   /* Run time stack overflow checking is performed if
   configCHECK_FOR_STACK_OVERFLOW is defined to 1 or 2. This hook function is
   called if a stack overflow is detected. */
   printf("vApplicationStackOverflowHook() %s\n", pcTaskName);
}
/* USER CODE END 4 */

/* USER CODE BEGIN 5 */
void vApplicationMallocFailedHook(void)
{
   /* vApplicationMallocFailedHook() will only be called if
   configUSE_MALLOC_FAILED_HOOK is set to 1 in FreeRTOSConfig.h. It is a hook
   function that will get called if a call to pvPortMalloc() fails.
   pvPortMalloc() is called internally by the kernel whenever a task, queue,
   timer or semaphore is created. It is also called by various parts of the
   demo application. If heap_1.c or heap_2.c are used, then the size of the
   heap available to pvPortMalloc() is defined by configTOTAL_HEAP_SIZE in
   FreeRTOSConfig.h, and the xPortGetFreeHeapSize() API function can be used
   to query the size of free heap space that remains (although it does not
   provide information on how the remaining heap might be fragmented). */
  printf("vApplicationMallocFailedHook()\n");
}
/* USER CODE END 5 */
